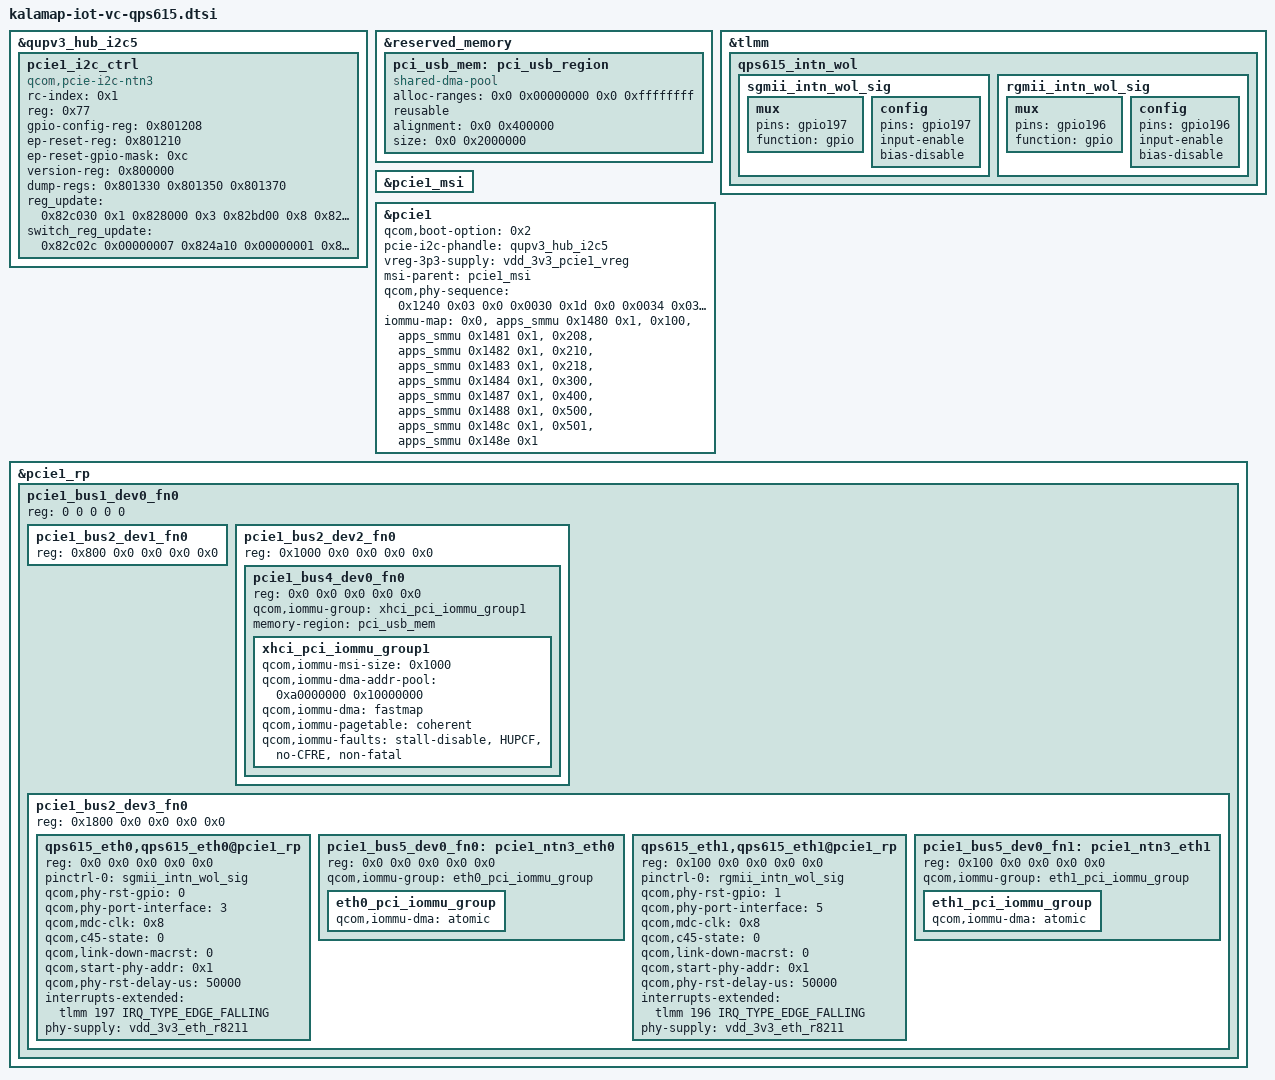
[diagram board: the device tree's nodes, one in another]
#include "kalama-iot-vc-regulator-sys.dtsi"

&qupv3_hub_i2c5 {
	status = "ok";
	pcie1_i2c_ctrl: pcie1_i2c_ctrl {
		compatible = "qcom,pcie-i2c-ntn3";
		rc-index = <0x1>;
		reg = <0x77>;
		gpio-config-reg = <0x801208>;
		ep-reset-reg = <0x801210>;
		ep-reset-gpio-mask = <0xc>;
		version-reg = <0x800000>;
		dump-regs = <0x801330 0x801350 0x801370>;
		reg_update = <0x82c030 0x1
				0x828000 0x3
				0x82bd00 0x8
				0x82c030 0x2
				0x828000 0x3
				0x82bd00 0x8
				0x82c030 0x8
				0x828000 0x1
				0x82bd00 0x8
				0x82c01c 0x10
				0x82c030 0xf
				0x828000 0xf
				0x82b268 0x2>;
		/* FOM for preset caluclation */
		switch_reg_update = <0x82c02c 0x00000007
					0x824a10 0x00000001
					0x82c030 0x00000008
					0x828000 0x00000001
					0x82b074 0x00000020
					0x82b2bc 0x00000001>;
	};
};

&reserved_memory {
	pci_usb_mem: pci_usb_region {
		compatible = "shared-dma-pool";
		alloc-ranges = <0x0 0x00000000 0x0 0xffffffff>;
		reusable;
		alignment = <0x0 0x400000>;
		size = <0x0 0x2000000>;
	};
};

&tlmm {
	qps615_intn_wol {
		sgmii_intn_wol_sig: sgmii_intn_wol_sig {
			mux {
				pins = "gpio197";
				function = "gpio";
			};

			config {
				pins = "gpio197";
				input-enable;
				bias-disable;
			};
		};

		rgmii_intn_wol_sig: rgmii_intn_wol_sig {
			mux {
				pins = "gpio196";
				function = "gpio";
			};

			config {
				pins = "gpio196";
				input-enable;
				bias-disable;
			};
		};
	};
};

&pcie1_msi {
	status = "ok";
};

&pcie1 {
	status = "ok";
	qcom,boot-option = <0x2>;
	pcie-i2c-phandle = <&qupv3_hub_i2c5>;
	vreg-3p3-supply = <&vdd_3v3_pcie1_vreg>;
	msi-parent = <&pcie1_msi>;
	qcom,phy-sequence = <0x1240 0x03 0x0
			0x0030 0x1d 0x0
			0x0034 0x03 0x0
			0x0078 0x01 0x0
			0x007c 0x00 0x0
			0x0080 0x51 0x0
			0x00ac 0x34 0x0
			0x0208 0x0c 0x0
			0x020c 0x0a 0x0
			0x0218 0x04 0x0
			0x0220 0x16 0x0
			0x0234 0x00 0x0
			0x029c 0x80 0x0
			0x02a0 0x7c 0x0
			0x02b4 0x05 0x0
			0x02e8 0x0a 0x0
			0x030c 0x0d 0x0
			0x0320 0x0b 0x0
			0x0348 0x1c 0x0
			0x0388 0x20 0x0
			0x0394 0x30 0x0
			0x03dc 0x09 0x0
			0x03f4 0x14 0x0
			0x03f8 0xb3 0x0
			0x03fc 0x58 0x0
			0x0400 0x9a 0x0
			0x0404 0x26 0x0
			0x0408 0xb6 0x0
			0x040c 0xee 0x0
			0x0410 0xdb 0x0
			0x0414 0xdb 0x0
			0x0418 0xa0 0x0
			0x041c 0xdf 0x0
			0x0420 0x78 0x0
			0x0424 0x76 0x0
			0x0428 0xff 0x0
			0x0830 0x1d 0x0
			0x0834 0x03 0x0
			0x0878 0x01 0x0
			0x087c 0x00 0x0
			0x0880 0x51 0x0
			0x08ac 0x34 0x0
			0x0a08 0x0c 0x0
			0x0a0c 0x0a 0x0
			0x0a18 0x04 0x0
			0x0a20 0x16 0x0
			0x0a34 0x00 0x0
			0x0a9c 0x80 0x0
			0x0aa0 0x7c 0x0
			0x0ab4 0x05 0x0
			0x0ae8 0x0a 0x0
			0x0b0c 0x0d 0x0
			0x0b20 0x0b 0x0
			0x0b48 0x1c 0x0
			0x0b88 0x20 0x0
			0x0b94 0x30 0x0
			0x0bdc 0x09 0x0
			0x0bf4 0x14 0x0
			0x0bf8 0xb3 0x0
			0x0bfc 0x58 0x0
			0x0c00 0x9a 0x0
			0x0c04 0x26 0x0
			0x0c08 0xb6 0x0
			0x0c0c 0xee 0x0
			0x0c10 0xdb 0x0
			0x0c14 0xdb 0x0
			0x0c18 0xa0 0x0
			0x0c1c 0xdf 0x0
			0x0c20 0x78 0x0
			0x0c24 0x76 0x0
			0x0c28 0xff 0x0
			0x0ea0 0x01 0x0
			0x0eb4 0x00 0x0
			0x0ec4 0x00 0x0
			0x0ec8 0x1f 0x0
			0x0ed4 0x12 0x0
			0x0ed8 0x12 0x0
			0x0edc 0xdb 0x0
			0x0ee0 0x9a 0x0
			0x0ee4 0x38 0x0
			0x0ee8 0xb6 0x0
			0x0eec 0x64 0x0
			0x0ef0 0x1f 0x0
			0x0ef4 0x1f 0x0
			0x0ef8 0x1f 0x0
			0x0efc 0x1f 0x0
			0x0f00 0x1f 0x0
			0x0f04 0x1f 0x0
			0x0f0c 0x1f 0x0
			0x0f14 0x1f 0x0
			0x0f1c 0x1f 0x0
			0x0f28 0x5b 0x0
			0x1000 0x26 0x0
			0x1004 0x03 0x0
			0x1010 0x06 0x0
			0x1014 0x16 0x0
			0x1018 0x36 0x0
			0x101c 0x04 0x0
			0x1020 0x0a 0x0
			0x1024 0x1a 0x0
			0x1028 0x68 0x0
			0x1030 0xab 0x0
			0x1034 0xaa 0x0
			0x1038 0x02 0x0
			0x103c 0x12 0x0
			0x1060 0xf8 0x0
			0x1064 0x01 0x0
			0x1070 0x06 0x0
			0x1074 0x16 0x0
			0x1078 0x36 0x0
			0x107c 0x0a 0x0
			0x1080 0x04 0x0
			0x1084 0x0d 0x0
			0x1088 0x41 0x0
			0x1090 0xab 0x0
			0x1094 0xaa 0x0
			0x1098 0x01 0x0
			0x109c 0x00 0x0
			0x10bc 0x0a 0x0
			0x10c0 0x01 0x0
			0x10cc 0x62 0x0
			0x10d0 0x02 0x0
			0x10d8 0x40 0x0
			0x10dc 0x14 0x0
			0x10e0 0x90 0x0
			0x10e4 0x82 0x0
			0x10f4 0x0f 0x0
			0x1110 0x08 0x0
			0x1120 0x46 0x0
			0x1124 0x04 0x0
			0x1140 0x14 0x0
			0x1164 0x34 0x0
			0x1170 0xa0 0x0
			0x1174 0x06 0x0
			0x1184 0x88 0x0
			0x1188 0x14 0x0
			0x1198 0x0f 0x0
			0x1378 0x2e 0x0
			0x1390 0xcc 0x0
			0x13f8 0x00 0x0
			0x13fc 0x22 0x0
			0x141c 0xc1 0x0
			0x1490 0x00 0x0
			0x14a0 0x16 0x0
			0x1420 0x40 0x0
			0x1508 0x02 0x0
			0x155c 0x2e 0x0
			0x157c 0x03 0x0
			0x1584 0x28 0x0
			0x13dc 0x04 0x0
			0x13e0 0x02 0x0
			0x1418 0xc0 0x0
			0x140c 0x1d 0x0
			0x158c 0x0f 0x0
			0x15ac 0xf2 0x0
			0x15c0 0xf2 0x0
			0x1200 0x00 0x0
			0x1244 0x03 0x0>;
	iommu-map = <0x0 &apps_smmu 0x1480 0x1>,
		<0x100 &apps_smmu 0x1481 0x1>,
		<0x208 &apps_smmu 0x1482 0x1>,
		<0x210 &apps_smmu 0x1483 0x1>,
		<0x218 &apps_smmu 0x1484 0x1>,
		<0x300 &apps_smmu 0x1487 0x1>,
		<0x400 &apps_smmu 0x1488 0x1>,
		<0x500 &apps_smmu 0x148c 0x1>,
		<0x501 &apps_smmu 0x148e 0x1>;
};

&pcie1_rp {
	#address-cells = <5>;
	#size-cells = <0>;
	/* BDF 1.0.0 */
	pcie1_bus1_dev0_fn0: pcie1_bus1_dev0_fn0 {
		reg = <0 0 0 0 0>;

		/* BDF 2.1.0 */
		pcie1_bus2_dev1_fn0: pcie1_bus2_dev1_fn0 {
			reg = <0x800 0x0 0x0 0x0 0x0>;
		};

		/* BDF 2.2.0 */
		pcie1_bus2_dev2_fn0: pcie1_bus2_dev2_fn0 {
			reg = <0x1000 0x0 0x0 0x0 0x0>;
			/* BDF 4.0.0 */
			pcie1_bus4_dev0_fn0: pcie1_bus4_dev0_fn0 {
				reg = <0x0 0x0 0x0 0x0 0x0>;
				qcom,iommu-group = <&xhci_pci_iommu_group1>;
				memory-region = <&pci_usb_mem>;
				#address-cells = <1>;
				#size-cells = <1>;
				xhci_pci_iommu_group1: xhci_pci_iommu_group1 {
					qcom,iommu-msi-size = <0x1000>;
					qcom,iommu-dma-addr-pool = <0xa0000000 0x10000000>;
					qcom,iommu-dma = "fastmap";
					qcom,iommu-pagetable = "coherent";
					qcom,iommu-faults = "stall-disable", "HUPCF", "no-CFRE",
							"non-fatal";
				};
			};
		};

		/* BDF 2.3.0 */
		pcie1_bus2_dev3_fn0: pcie1_bus2_dev3_fn0 {
			reg = <0x1800 0x0 0x0 0x0 0x0>;
			qps615_eth0,qps615_eth0@pcie1_rp {
				reg = <0x0 0x0 0x0 0x0 0x0>;
				pinctrl-names = "default";
				pinctrl-0 = <&sgmii_intn_wol_sig>;
				qcom,phy-rst-gpio = <0>;
				qcom,phy-port-interface = <3>; //ENABLE_SGMII_INTERFACE
				qcom,mdc-clk = <0x8>; //TC956XMAC_XGMAC_MDC_CSR_62 = 0x8
				qcom,c45-state = <0>; //false
				qcom,link-down-macrst = <0>; //disable
				qcom,start-phy-addr = <0x1>; //RTL8211F supports phy addr 1 to 7
				qcom,phy-rst-delay-us = <50000>;
				interrupts-extended = <&tlmm 197 IRQ_TYPE_EDGE_FALLING>;
				interrupt-names = "wol_irq";
				phy-supply = <&vdd_3v3_eth_r8211>;
				#address-cells = <1>;
				#size-cells = <1>;
			};

			/* BDF 5.0.0 */
			pcie1_bus5_dev0_fn0: pcie1_ntn3_eth0 {
				reg = <0x0 0x0 0x0 0x0 0x0>;
				qcom,iommu-group = <&eth0_pci_iommu_group>;
				eth0_pci_iommu_group: eth0_pci_iommu_group {
					qcom,iommu-dma = "atomic";
				};
			};

			qps615_eth1,qps615_eth1@pcie1_rp {
				reg = <0x100 0x0 0x0 0x0 0x0>;
				pinctrl-names = "default";
				pinctrl-0 = <&rgmii_intn_wol_sig>;
				qcom,phy-rst-gpio = <1>;
				qcom,phy-port-interface = <5>; //ENABLE_RGMII_ID_INTERFACE
				qcom,mdc-clk = <0x8>; //TC956XMAC_XGMAC_MDC_CSR_62 = 0x8
				qcom,c45-state = <0>; //false
				qcom,link-down-macrst = <0>; //disable
				qcom,start-phy-addr = <0x1>; //RTL8211F supports phy addr 1 to 7
				qcom,phy-rst-delay-us = <50000>;
				interrupts-extended = <&tlmm 196 IRQ_TYPE_EDGE_FALLING>;
				interrupt-names = "wol_irq";
				phy-supply = <&vdd_3v3_eth_r8211>;
				#address-cells = <1>;
				#size-cells = <1>;
			};

			/* BDF 5.0.1 */
			pcie1_bus5_dev0_fn1: pcie1_ntn3_eth1 {
				reg = <0x100 0x0 0x0 0x0 0x0>;
				qcom,iommu-group = <&eth1_pci_iommu_group>;
				eth1_pci_iommu_group: eth1_pci_iommu_group {
					qcom,iommu-dma = "atomic";
				};
			};
		};
	};
};
